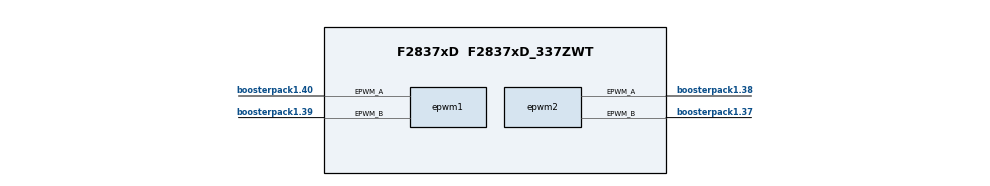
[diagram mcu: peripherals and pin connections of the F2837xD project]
/**
 * @cliArgs --board "/boards/LAUNCHXL_F28379D" --device "F2837xD" --part "F2837xD_337ZWT" --package "F2837xD_337ZWT" --context "CPU1" --product "C2000WARE@5.04.00.00"
 * @versions {"tool":"1.22.0+3893"}
 */

/**
 * Import the modules used in this configuration.
 */
const led   = scripting.addModule("/driverlib/board_components/led", {}, false);
const led1  = led.addInstance();
const epwm  = scripting.addModule("/driverlib/epwm.js", {}, false);
const epwm1 = epwm.addInstance();
const epwm2 = epwm.addInstance();

/**
 * Write custom configuration values to the imported modules.
 */
led1.$name     = "myBoardLED0";
led1.$hardware = system.deviceData.board.components.LED5;

epwm1.$name                                                      = "myEPWM0";
epwm1.epwmTimebase_hsClockDiv                                    = "EPWM_HSCLOCK_DIVIDER_1";
epwm1.epwmTimebase_period                                        = 50000;
epwm1.epwmTimebase_counterMode                                   = "EPWM_COUNTER_MODE_UP_DOWN";
epwm1.epwmCounterCompare_cmpA                                    = 25000;
epwm1.epwmCounterCompare_shadowLoadModeCMPA                      = "EPWM_COMP_LOAD_ON_CNTR_PERIOD";
epwm1.epwmActionQualifier_EPWM_AQ_OUTPUT_A_shadowMode            = true;
epwm1.epwmActionQualifier_EPWM_AQ_OUTPUT_A_shadowEvent           = "EPWM_AQ_LOAD_ON_CNTR_PERIOD";
epwm1.epwmActionQualifier_EPWM_AQ_OUTPUT_A_ON_TIMEBASE_UP_CMPA   = "EPWM_AQ_OUTPUT_HIGH";
epwm1.epwmActionQualifier_EPWM_AQ_OUTPUT_A_ON_TIMEBASE_DOWN_CMPA = "EPWM_AQ_OUTPUT_LOW";
epwm1.epwm.$assign                                               = "EPWM1";
epwm1.epwm.epwm_aPin.$assign                                     = "boosterpack1.40";
epwm1.epwm.epwm_bPin.$assign                                     = "boosterpack1.39";
scripting.suppress("Connected to hardware,@@@.+?@@@ is connected to EPWM1 BP on the LaunchPad F28379D\\. Consider selecting it in \'use hardware\' above\\. @@@.+?@@@", epwm1.epwm, "epwm_aPin");
scripting.suppress("Connected to hardware,@@@.+?@@@ is connected to EPWM1 BP on the LaunchPad F28379D\\. Consider selecting it in \'use hardware\' above\\. @@@.+?@@@", epwm1.epwm, "epwm_bPin");

epwm2.$name                                             = "myEPWM1";
epwm2.epwmTimebase_hsClockDiv                           = "EPWM_HSCLOCK_DIVIDER_1";
epwm2.epwmTimebase_counterMode                          = "EPWM_COUNTER_MODE_UP";
epwm2.epwmTimebase_period                               = 12499;
epwm2.epwmEventTrigger_EPWM_SOC_A_triggerEnable         = true;
epwm2.epwmEventTrigger_EPWM_SOC_A_triggerSource         = "EPWM_SOC_TBCTR_PERIOD";
epwm2.epwmEventTrigger_EPWM_SOC_A_triggerEventPrescalar = "1";
epwm2.epwm.$assign                                      = "EPWM2";
epwm2.epwm.epwm_aPin.$assign                            = "boosterpack1.38";
epwm2.epwm.epwm_bPin.$assign                            = "boosterpack1.37";
scripting.suppress("Connected to hardware,@@@.+?@@@ is connected to EPWM2 BP on the LaunchPad F28379D\\. Consider selecting it in \'use hardware\' above\\. @@@.+?@@@", epwm2.epwm, "epwm_aPin");
scripting.suppress("Connected to hardware,@@@.+?@@@ is connected to EPWM2 BP on the LaunchPad F28379D\\. Consider selecting it in \'use hardware\' above\\. @@@.+?@@@", epwm2.epwm, "epwm_bPin");

/**
 * Pinmux solution for unlocked pins/peripherals. This ensures that minor changes to the automatic solver in a future
 * version of the tool will not impact the pinmux you originally saw.  These lines can be completely deleted in order to
 * re-solve from scratch.
 */
led1.gpio.gpioPin.$suggestSolution = "GPIO34";
